# STM32H503 register map
File version: 0.3
CPU: CM33 r0p0, little endian, MPU, FPU, 4 interrupt priority bits
Registers are 32-bit, read-write, reset 0x0 unless marked. A register's access mark holds for its fields unless they carry their own. Offsets are from the block's base; [hi:lo] are bit positions; <NAME> marks a mode.

## SBS — System configuration, boot and security
Base 0x44000400
0x10 HDPLCR reset 0xB4 — SBS temporal isolation control register
  [7:0] INCR_HDPL — increment HDPL value Other: all other values allow a HDPL level increment.
0x14 HDPLSR ro reset not defined — SBS temporal isolation status register
  [7:0] HDPL — temporal isolation level This bitfield returns the current temporal isolation level.
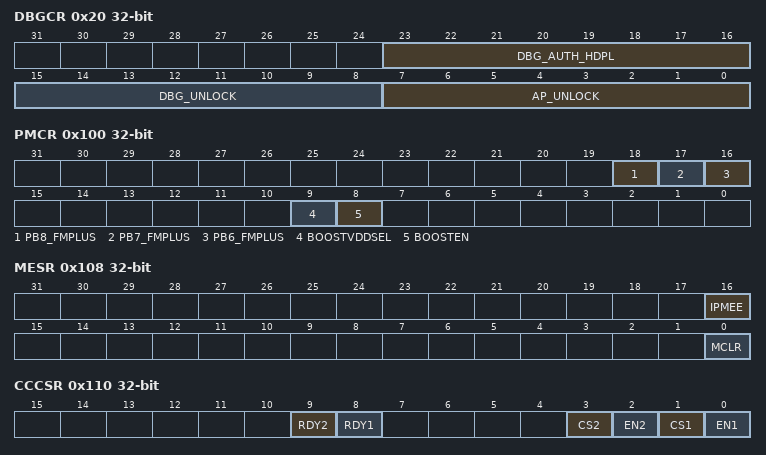
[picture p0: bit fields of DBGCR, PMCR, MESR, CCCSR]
0x20 DBGCR — SBS debug control register
  [23:16] DBG_AUTH_HDPL — authenticated debug temporal isolation level Writing to this bitfield defines at which HDPL the authenticated debug opens. Note: Writing any other values is ignored. Reading any other value means the debug never opens.
  [15:8] DBG_UNLOCK — debug unlock when DBG_AUTH_HDPL is reached Write 0xB4 to this bitfield to open the debug when HDPL in SBS_HDPLSR equals to DBG_AUTH_HDPL in this register.
  [7:0] AP_UNLOCK — access port unlock Write 0xB4 to this bitfield to open the device access port.
0x24 DBGLOCKR reset 0xB4 — SBS debug lock register
  [7:0] DBGCFG_LOCK — debug configuration lock Reading this bitfield returns 0x6A if the bitfield value is different from 0xB4. 0xC3 is the recommended value to lock the debug configuration using this bitfield. Other: Writes to SBS_DBGCR ignored
0x100 PMCR — SBS product mode and configuration register
  [18] PB8_FMPLUS — Fast-mode Plus command on PB(8)
  [17] PB7_FMPLUS — Fast-mode Plus command on PB(7)
  [16] PB6_FMPLUS — Fast-mode Plus command on PB(6)
  [9] BOOSTVDDSEL — booster V<sub>DD</sub> selection Note: Booster must not be used when V<sub>DDA</sub> < 2.7 V, but V<sub>DD</sub> > 2.7 V (add current consumption). Note: When both V<sub>DD</sub> < 2.7 V and V<sub>DDA</sub> < 2.7 V, booster is needed to get full AC performances from I/O analog switches.
  [8] BOOSTEN — booster enable Set this bit to reduce the total harmonic distortion of the analog switch when the processor supply is below 2.7 V. The booster can be activated to guaranty AC performance on analog switch when the supply is below 2.7 V. When the booster is activated, the analog switch performances are the same as with the full voltage range.
0x104 FPUIMR reset 0x1F — SBS FPU interrupt mask register
  [5:0] FPU_IE — FPU interrupt enable Set and cleared by software to enable the Cortex-M33 FPU interrupts FPU_IE[5]: inexact interrupt enable (interrupt disabled at reset) FPU_IE[4]: input abnormal interrupt enable FPU_IE[3]: overflow interrupt enable FPU_IE[2]: underflow interrupt enable FPU_IE[1]: divide-by-zero interrupt enable FPU_IE[0]: invalid operation interrupt enable
0x108 MESR — SBS memory erase status register
  [16] IPMEE — end-of-erase status for ICACHE This bit shows the status of the protection for ICACHE. It is set by hardware and reset by software.
  [0] MCLR — erase after reset status This bit shows the status of the protection for SRAM2, BKPRAM, ICACHE, ICACHE. It is set by hardware and reset by software
0x110 CCCSR access per field — SBS compensation cell for I/Os control and status register
  [9] RDY2 ro — VDDIO2 compensation cell ready flag This bit provides the status of the VDDIO2 compensation cell.
  [8] RDY1 ro — VDDIO compensation cell ready flag This bit provides the status of the compensation cell.
  [3] CS2 rw — code selection for VDDIO2 power rail (reset value set to 1) This bit selects the code to be applied for the I/O compensation cell.
  [2] EN2 rw — enable compensation cell for VDDIO2 power rail This bit enables the I/O compensation cell.
  [1] CS1 rw — code selection for VDDIO power rail (reset value set to 1) This bit selects the code to be applied for the I/O compensation cell.
  [0] EN1 rw — enable compensation cell for VDDIO power rail This bit enables the I/O compensation cell.
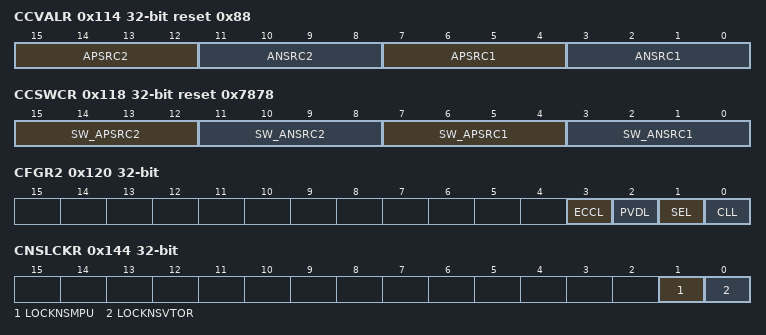
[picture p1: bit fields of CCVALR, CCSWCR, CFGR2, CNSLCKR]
0x114 CCVALR ro reset 0x88 — SBS compensation cell for I/Os value register
  [15:12] APSRC2 — compensation value for the PMOS transistor This value is provided by the cell and must be interpreted by the processor to compensate the slew rate in the functional range.
  [11:8] ANSRC2 — Compensation value for the NMOS transistor This value is provided by the cell and must be interpreted by the processor to compensate the slew rate in the functional range.
  [7:4] APSRC1 — compensation value for the PMOS transistor This value is provided by the cell and must be interpreted by the processor to compensate the slew rate in the functional range.
  [3:0] ANSRC1 — compensation value for the NMOS transistor This value is provided by the cell and must be interpreted by the processor to compensate the slew rate in the functional range.
0x118 CCSWCR reset 0x7878 — SBS compensation cell for I/Os software code register
  [15:12] SW_APSRC2 — PMOS compensation code for the V<sub>DDIO</sub> power rails This bitfield is written by software to define an I/O compensation cell code for PMOS transistors of the VDDIO power rail. This code is applied to the I/O when CS2 is set in SBS_CCSR.
  [11:8] SW_ANSRC2 — NMOS compensation code for VDDIO power rails This bitfield is written by software to define an I/O compensation cell code for NMOS transistors of the VDD power rail. This code is applied to the I/O when CS2 is set in SBS_CCSR.
  [7:4] SW_APSRC1 — PMOS compensation code for the VDD power rails This bitfield is written by software to define an I/O compensation cell code for PMOS transistors of the VDDIO power rail. This code is applied to the I/O when CS1 is set in SBS_CCSR.
  [3:0] SW_ANSRC1 — NMOS compensation code for VDD power rails This bitfield is written by software to define an I/O compensation cell code for NMOS transistors of the VDD power rail. This code is applied to the I/O when CS1 is set in SBS_CCSR.
0x120 CFGR2 — SBS Class B register
  [3] ECCL — ECC lock This bit is set and cleared by software. It can be used to enable and lock the Flash memory double ECC error with break input of TIM1.
  [2] PVDL — PVD lock This bit is set by software and cleared only by a system reset. It can be used to enable and lock the PVD connection with TIM1 break inputs.
  [1] SEL — SRAM ECC error lock This bit is set by software and cleared only by a system reset. It can be used to enable and lock the SRAM double ECC error signal with break input of TIM1.
  [0] CLL — core lockup lock This bit is set by software and cleared only by a system reset. It can be used to enable and lock the lockup (HardFault) output of Cortex-M33 with TIM1 break inputs.
0x144 CNSLCKR — SBS CPU lock register
  [1] LOCKNSMPU — MPU register lock This bit is set by software and cleared only by a system reset. When set, this bit disables write access to MPU_CTRL_NS, MPU_RNR_NS and MPU_RBAR_NS registers.
  [0] LOCKNSVTOR — VTOR_NS register lock This bit is set by software and cleared only by a system reset.
0x14C ECCNMIR — SBS flift ECC NMI mask register
  [0] ECCNMI_MASK_EN — NMI behavior setup when a double ECC error occurs on flitf data part
